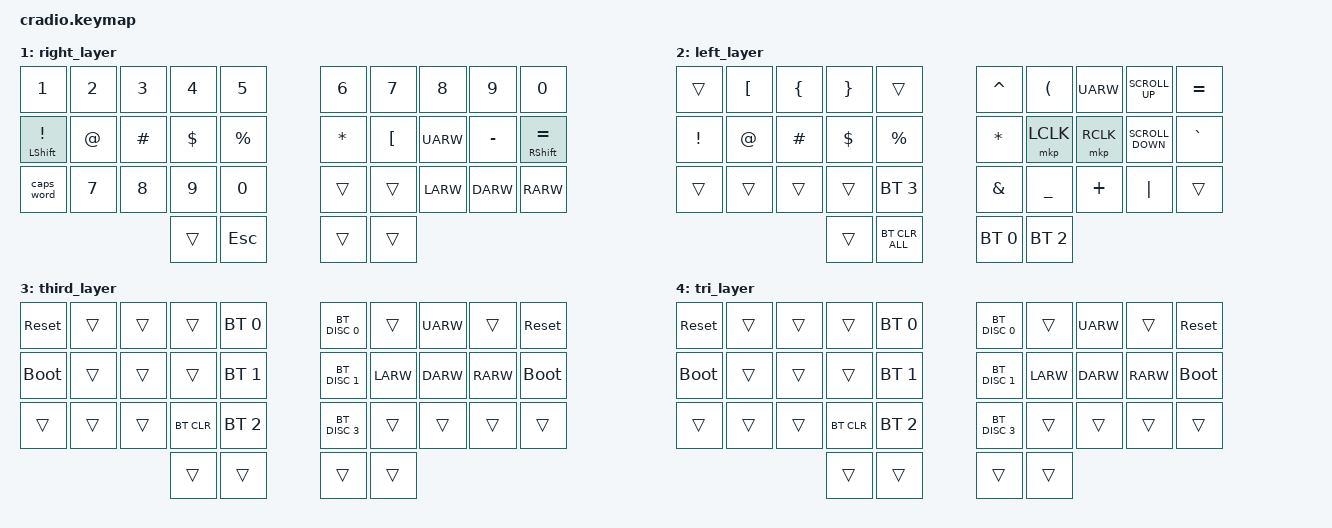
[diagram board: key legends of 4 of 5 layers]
// Copyright (c) 2022 The ZMK Contributors
// SPDX-License-Identifier: MIT

#include <behaviors.dtsi>
#include <dt-bindings/zmk/keys.h>
#include <dt-bindings/zmk/bt.h>
#include <dt-bindings/zmk/mouse.h>


// Home row mods macro
#define HRML(k1,k2,k3,k4) &ht LSHFT k1  &ht LALT k2  &ht LCTRL k3  &ht LGUI k4
#define HRMR(k1,k2,k3,k4) &ht RGUI k1  &ht RALT k2  &ht RGUI k3  &ht RSHFT k4

/ {
    behaviors {
        ht: hold_tap {
            compatible = "zmk,behavior-hold-tap";
            #binding-cells = <2>;
            flavor = "tap-preferred";
            tapping-term-ms = <220>;
            quick-tap-ms = <150>;
            require-prior-idle-ms = <100>;
            bindings = <&kp>, <&kp>;
        };
    };

    conditional_layers {
        compatible = "zmk,conditional-layers";
        tri_layer {
            if-layers = <1 2>;
            then-layer = <4>;
        };
    };

    keymap {
        compatible = "zmk,keymap";
        default_layer {
            bindings = <
        //╭──────────┬──────────┬──────────┬──────────┬──────────╮   ╭──────────┬──────────┬──────────┬──────────┬──────────╮
        //│  Q       │  W       │  E       │  R       │  T       │   │  Y       │  U       │  I       │  O       │  P       │
            &kp Q       &kp W      &kp F      &kp P      &kp B         &kp J      &kp L      &kp U      &kp Y      &kp SEMI
        //├──────────┼──────────┼──────────┼──────────┼──────────┤   ├──────────┼──────────┼──────────┼──────────┼──────────┤
        //│  A       │  S       │  D       │  F       │  G       │   │  H       │  J       │  K       │  L       │ ' "      │
            HRML(A,        S,         R,         T)     &kp G          &kp M      HRMR(N,        E,         I,        O)
        //├──────────┼──────────┼──────────┼──────────┼──────────┤   ├──────────┼──────────┼──────────┼──────────┼──────────┤
        //│  Z       │  X       │  C       │  V       │  B       │   │  N       │  M       │ , <      │ . >      │ / ?      │
            &kp Z      &kp X      &kp C      &kp D      &kp V          &kp K      &kp H      &kp COMMA  &kp DOT    &kp FSLH
        //╰──────────┴──────────┴──────────┼──────────┼──────────┤   ├──────────┼──────────┼──────────┴──────────┴──────────╯
                                            &lt 3 TAB	  &kp BSPC    &lt 2 SPACE  &lt 1 ENTER
        //                                 ╰──────────┴──────────╯   ╰──────────┴──────────╯
            >;
        };
    // number symbols
        right_layer {
            bindings = <
        //╭──────────┬──────────┬──────────┬──────────┬──────────╮   ╭──────────┬──────────┬──────────┬──────────┬──────────╮
        //│ 1        │  2      │  3       │  4       │       5   │   │ 6         │ 7       │ 8        │ 9        │  0       │
            &kp N1    &kp N2     &kp N3     &kp N4     &kp N5         &kp N6       &kp N7      &kp N8      &kp N9    &kp N0
        //├──────────┼──────────┼──────────┼──────────┼──────────┤   ├──────────┼──────────┼──────────┼──────────┼──────────┤
        //│ !         │  @    │  5       │  6       │             │   │ *        │ DOWN     │ UP       │ UP    │  ;        │
        &ht LSHFT EXCL    &kp AT     &kp HASH     &kp DLLR  &kp PRCNT     &kp ASTRK   &kp LBKT   &kp UARW   &kp MINUS   &ht RSHFT EQUAL
        //├──────────┼──────────┼──────────┼──────────┼──────────┤   ├──────────┼──────────┼──────────┼──────────┼──────────┤
        //│ CAPS     │  7       │  8       │  9       │  0       │   │          │          │   LEF    │   DOWN   │      RIGHT    │
           &caps_word  &kp N7     &kp N8     &kp N9     &kp N0         &trans     &trans     &kp LARW     &kp DARW     &kp RARW
        //╰──────────┴──────────┴──────────┼──────────┼──────────┤   ├──────────┼──────────┼──────────┴──────────┴──────────╯
                                             &trans     &kp ESC        &trans     &trans
        //                                 ╰──────────┴──────────╯   ╰──────────┴──────────╯
            >;
        };
// naviagation
        left_layer {
            bindings = <
        //╭──────────┬──────────┬──────────┬──────────┬──────────╮   ╭──────────┬──────────┬──────────┬──────────┬──────────╮
        //│          │  [       │  {       │  }       │          │   │  ^       │  (       │  )       │         │  ~       │
            &trans     &kp LBKT   &kp LBRC   &kp RBRC   &trans         &kp CARET  &kp LPAR   &kp UARW   &kp K_SCROLL_UP   &kp EQUAL
        //├──────────┼──────────┼──────────┼──────────┼──────────┤   ├──────────┼──────────┼──────────┼──────────┼──────────┤
        //│  !       │  @       │  #       │  $       │  %       │   │  *       │left bracket  │  =       │  \       │  `       │
            &kp EXCL   &kp AT     &kp HASH   &kp DLLR   &kp PRCNT      &kp ASTRK  &mkp LCLK &mkp RCLK  &kp K_SCROLL_DOWN   &kp GRAVE
        //├──────────┼──────────┼──────────┼──────────┼──────────┤   ├──────────┼──────────┼──────────┼──────────┼──────────┤
        //│          │          │          │          │          │   │  &       │  _       │  +       │  │       │          │
            &trans     &trans     &trans     &trans    &bt BT_SEL 3         &kp AMPS   &kp UNDER  &kp PLUS   &kp PIPE   &trans
        //╰──────────┴──────────┴──────────┼──────────┼──────────┤   ├──────────┼──────────┼──────────┴──────────┴──────────╯
                                             &trans     &bt BT_CLR_ALL  &bt BT_SEL 0     &bt BT_SEL 2
        //                                 ╰──────────┴──────────╯   ╰──────────┴──────────╯
            >;
        };
// bluetooth n systems
        third_layer {
            bindings = <
        //╭──────────┬──────────┬──────────┬──────────┬──────────╮   ╭──────────┬──────────┬──────────┬──────────┬──────────╮
        //│ RESET    │          │          │          │PROFILE 0 │   │          │          │          │          │  RESET   │
           &sys_reset  &trans     &trans     &trans    &bt BT_SEL 0  &bt BT_DISC 0  &trans   &kp UARW     &trans    &sys_reset
        //├──────────┼──────────┼──────────┼──────────┼──────────┤   ├──────────┼──────────┼──────────┼──────────┼──────────┤
        //│BOOTLOADER│          │          │          │PROFILE 1 │   │          │          │          │          │BOOTLOADER│
          &bootloader  &trans     &trans     &trans    &bt BT_SEL 1  &bt BT_DISC 1  &kp LARW  &kp DARW   &kp RARW    &bootloader
        //├──────────┼──────────┼──────────┼──────────┼──────────┤   ├──────────┼──────────┼──────────┼──────────┼──────────┤
        //│          │          │          │ CLEAR BT │PROFILE 2 │   │          │          │          │          │          │
            &trans     &trans     &trans    &bt BT_CLR &bt BT_SEL 2    &bt BT_DISC 3     &trans     &trans     &trans     &trans
        //╰──────────┴──────────┴──────────┼──────────┼──────────┤   ├──────────┼──────────┼──────────┴──────────┴──────────╯
                                             &trans     &trans         &trans     &trans
        //                                 ╰──────────┴──────────╯   ╰──────────┴──────────╯
>;
        };
// bluetooth n systems
        tri_layer {
            bindings = <
        //╭──────────┬──────────┬──────────┬──────────┬──────────╮   ╭──────────┬──────────┬──────────┬──────────┬──────────╮
        //│ RESET    │          │          │          │PROFILE 0 │   │          │          │          │          │  RESET   │
           &sys_reset  &trans     &trans     &trans    &bt BT_SEL 0  &bt BT_DISC 0  &trans   &kp UARW     &trans    &sys_reset
        //├──────────┼──────────┼──────────┼──────────┼──────────┤   ├──────────┼──────────┼──────────┼──────────┼──────────┤
        //│BOOTLOADER│          │          │          │PROFILE 1 │   │          │          │          │          │BOOTLOADER│
          &bootloader  &trans     &trans     &trans    &bt BT_SEL 1  &bt BT_DISC 1  &kp LARW  &kp DARW   &kp RARW    &bootloader
        //├──────────┼──────────┼──────────┼──────────┼──────────┤   ├──────────┼──────────┼──────────┼──────────┼──────────┤
        //│          │          │          │ CLEAR BT │PROFILE 2 │   │          │          │          │          │          │
            &trans     &trans     &trans    &bt BT_CLR &bt BT_SEL 2    &bt BT_DISC 3     &trans     &trans     &trans     &trans
        //╰──────────┴──────────┴──────────┼──────────┼──────────┤   ├──────────┼──────────┼──────────┴──────────┴──────────╯
                                             &trans     &trans         &trans     &trans
        //                                 ╰──────────┴──────────╯   ╰──────────┴──────────╯


>;
        };
    };
};
